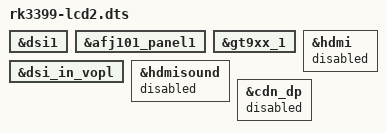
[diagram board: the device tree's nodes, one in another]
/dts-v1/;
/plugin/;

/ {
	fragment@0 {
		target = <&dsi1>;
		__overlay__ {
			status = "okay";
		};
	};

	fragment@1 {
		target = <&afj101_panel1>;
		__overlay__ {
			status = "okay";
		};
	};

	fragment@2 {
		target = <&gt9xx_1>;
		__overlay__ {
			status = "okay";
		};
	};

	fragment@3 {
		target = <&dsi_in_vopl>;
		__overlay__ {
			status = "okay";
		};
	};

	fragment@4 {
		target = <&hdmi>;
		__overlay__ {
			status = "disabled";
		};
	};

	fragment@5 {
		target = <&hdmisound>;
		__overlay__ {
			status = "disabled";
		};
	};

	fragment@6 {
		target = <&cdn_dp>;
		__overlay__ {
			status = "disabled";
		};
	};
};
